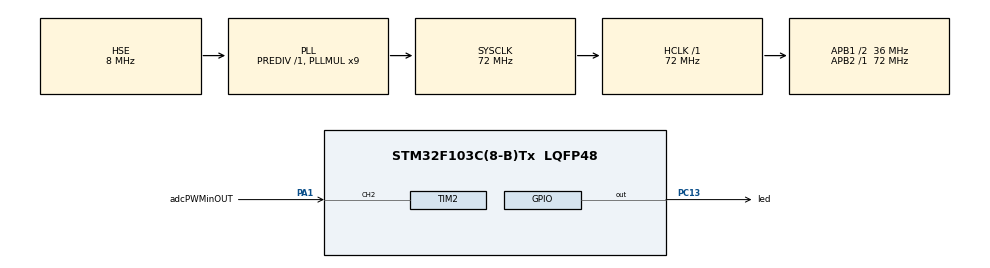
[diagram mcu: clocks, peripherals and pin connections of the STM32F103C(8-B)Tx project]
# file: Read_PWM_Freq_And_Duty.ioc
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Mcu.Family=STM32F1
Mcu.Name=STM32F103C(8-B)Tx
Mcu.Package=LQFP48
NVIC.PriorityGroup=NVIC_PRIORITYGROUP_4
NVIC.TIM2_IRQn=true\:1\:0\:true\:false\:true\:true\:true\:true
PA1.GPIO_Label=adcPWMinOUT
PA1.Signal=S_TIM2_CH2
PA13.Mode=Serial_Wire
PA13.Signal=SYS_JTMS-SWDIO
PA14.Mode=Serial_Wire
PA14.Signal=SYS_JTCK-SWCLK
PC13-TAMPER-RTC.GPIO_Label=led
PC13-TAMPER-RTC.Signal=GPIO_Output
PD0-OSC_IN.Mode=HSE-External-Oscillator
PD0-OSC_IN.Signal=RCC_OSC_IN
PD1-OSC_OUT.Mode=HSE-External-Oscillator
PD1-OSC_OUT.Signal=RCC_OSC_OUT
ProjectManager.HeapSize=0x200
ProjectManager.StackSize=0x400
ProjectManager.TargetToolchain=STM32CubeIDE
RCC.ADCPresc=RCC_ADCPCLK2_DIV8
RCC.AHBFreq_Value=72000000
RCC.APB1CLKDivider=RCC_HCLK_DIV2
RCC.APB1Freq_Value=36000000
RCC.APB1TimFreq_Value=72000000
RCC.APB2Freq_Value=72000000
RCC.APB2TimFreq_Value=72000000
RCC.HCLKFreq_Value=72000000
RCC.PLLMUL=RCC_PLL_MUL9
RCC.PLLSourceVirtual=RCC_PLLSOURCE_HSE
RCC.SYSCLKFreq_VALUE=72000000
RCC.SYSCLKSource=RCC_SYSCLKSOURCE_PLLCLK
RCC.USBFreq_Value=72000000
SH.S_TIM2_CH2.0=TIM2_CH2,PWM_Input_2
TIM2.Period=65535
TIM2.Prescaler=5-1
VP_TIM2_VS_ClockSourceINT.Mode=Internal
board=custom

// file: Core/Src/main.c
/* USER CODE BEGIN Header */
/**
  ******************************************************************************
  * @file           : main.c
  * @brief          : Main program body
  ******************************************************************************
  * @attention
  *
  * <h2><center>&copy; Copyright (c) 2025 STMicroelectronics.
  * All rights reserved.</center></h2>
  *
  * This software component is licensed by ST under Ultimate Liberty license
  * SLA0044, the "License"; You may not use this file except in compliance with
  * the License. You may obtain a copy of the License at:
  *                             www.st.com/SLA0044
  *
  ******************************************************************************
  */
/* USER CODE END Header */
#include "main.h"

/* USER CODE BEGIN Includes */
#include <math.h>
/* USER CODE END Includes */

/* USER CODE BEGIN PTD */
typedef struct {
	TIM_HandleTypeDef *htim;
	int32_t freq;
	int32_t dutyCycle;
	uint32_t capVal1;
	uint32_t capVal2;
} PWM_In;
/* USER CODE END PTD */

TIM_HandleTypeDef htim2;

/* USER CODE BEGIN PV */
PWM_In AS5600;
float AS5600_deg = 0;
/* USER CODE END PV */

void SystemClock_Config(void);
static void MX_GPIO_Init(void);
static void MX_TIM2_Init(void);

/* USER CODE BEGIN 0 */
float map_float_(float x, float in_min, float in_max, float out_min, float out_max) {
  return (x - in_min) * (out_max - out_min) / (in_max - in_min) + out_min;
}

void HAL_TIM_IC_CaptureCallback(TIM_HandleTypeDef *htim) {
	if (htim == &htim2) {
		if (htim2.Channel == HAL_TIM_ACTIVE_CHANNEL_2) {
			AS5600.capVal2 = htim2.Instance->CCR2; // get signal rising counter
			if (AS5600.capVal2) {
				AS5600.freq = (SystemCoreClock
						/ (htim2.Instance->PSC + 1)) / (AS5600.capVal2); //calculate freq with sysclock devide with htim psc
				AS5600.capVal1 = htim2.Instance->CCR1; //get signal falling counter
				AS5600.dutyCycle = 10000
						- (10000 * AS5600.capVal1 / AS5600.capVal2);
			}

		}
	}
}
/* USER CODE END 0 */

int main(void)
{

  /* MCU Configuration--------------------------------------------------------*/

  /* Reset of all peripherals, Initializes the Flash interface and the Systick. */
  HAL_Init();

  /* Configure the system clock */
  SystemClock_Config();

  /* Initialize all configured peripherals */
  MX_GPIO_Init();
  MX_TIM2_Init();
  /* USER CODE BEGIN 2 */
  HAL_TIM_IC_Start_IT(&htim2, TIM_CHANNEL_2);
  HAL_TIM_IC_Start_IT(&htim2, TIM_CHANNEL_1);
  /* USER CODE END 2 */

  /* Infinite loop */
  /* USER CODE BEGIN WHILE */
  while (1)
  {
	  AS5600_deg = map_float_((float)AS5600.dutyCycle, 0.0f, 10000.0f, 0.0f, 360.0f);
	  HAL_GPIO_TogglePin(led_GPIO_Port, led_Pin);
	  HAL_Delay(100);
    /* USER CODE END WHILE */

  }
}

void SystemClock_Config(void)
{
  RCC_OscInitTypeDef RCC_OscInitStruct = {0};
  RCC_ClkInitTypeDef RCC_ClkInitStruct = {0};

  /** Initializes the RCC Oscillators according to the specified parameters
  * in the RCC_OscInitTypeDef structure.
  */
  RCC_OscInitStruct.OscillatorType = RCC_OSCILLATORTYPE_HSE;
  RCC_OscInitStruct.HSEState = RCC_HSE_ON;
  RCC_OscInitStruct.HSEPredivValue = RCC_HSE_PREDIV_DIV1;
  RCC_OscInitStruct.HSIState = RCC_HSI_ON;
  RCC_OscInitStruct.PLL.PLLState = RCC_PLL_ON;
  RCC_OscInitStruct.PLL.PLLSource = RCC_PLLSOURCE_HSE;
  RCC_OscInitStruct.PLL.PLLMUL = RCC_PLL_MUL9;
  if (HAL_RCC_OscConfig(&RCC_OscInitStruct) != HAL_OK)
  {
    Error_Handler();
  }
  /** Initializes the CPU, AHB and APB buses clocks
  */
  RCC_ClkInitStruct.ClockType = RCC_CLOCKTYPE_HCLK|RCC_CLOCKTYPE_SYSCLK
                              |RCC_CLOCKTYPE_PCLK1|RCC_CLOCKTYPE_PCLK2;
  RCC_ClkInitStruct.SYSCLKSource = RCC_SYSCLKSOURCE_PLLCLK;
  RCC_ClkInitStruct.AHBCLKDivider = RCC_SYSCLK_DIV1;
  RCC_ClkInitStruct.APB1CLKDivider = RCC_HCLK_DIV2;
  RCC_ClkInitStruct.APB2CLKDivider = RCC_HCLK_DIV1;

  if (HAL_RCC_ClockConfig(&RCC_ClkInitStruct, FLASH_LATENCY_2) != HAL_OK)
  {
    Error_Handler();
  }
}

static void MX_TIM2_Init(void)
{

  TIM_ClockConfigTypeDef sClockSourceConfig = {0};
  TIM_SlaveConfigTypeDef sSlaveConfig = {0};
  TIM_IC_InitTypeDef sConfigIC = {0};
  TIM_MasterConfigTypeDef sMasterConfig = {0};

  htim2.Instance = TIM2;
  htim2.Init.Prescaler = 5-1;
  htim2.Init.CounterMode = TIM_COUNTERMODE_UP;
  htim2.Init.Period = 65535;
  htim2.Init.ClockDivision = TIM_CLOCKDIVISION_DIV1;
  htim2.Init.AutoReloadPreload = TIM_AUTORELOAD_PRELOAD_DISABLE;
  if (HAL_TIM_Base_Init(&htim2) != HAL_OK)
  {
    Error_Handler();
  }
  sClockSourceConfig.ClockSource = TIM_CLOCKSOURCE_INTERNAL;
  if (HAL_TIM_ConfigClockSource(&htim2, &sClockSourceConfig) != HAL_OK)
  {
    Error_Handler();
  }
  if (HAL_TIM_IC_Init(&htim2) != HAL_OK)
  {
    Error_Handler();
  }
  sSlaveConfig.SlaveMode = TIM_SLAVEMODE_RESET;
  sSlaveConfig.InputTrigger = TIM_TS_TI2FP2;
  sSlaveConfig.TriggerPolarity = TIM_INPUTCHANNELPOLARITY_FALLING;
  sSlaveConfig.TriggerPrescaler = TIM_ICPSC_DIV1;
  sSlaveConfig.TriggerFilter = 0;
  if (HAL_TIM_SlaveConfigSynchro(&htim2, &sSlaveConfig) != HAL_OK)
  {
    Error_Handler();
  }
  sConfigIC.ICPolarity = TIM_INPUTCHANNELPOLARITY_RISING;
  sConfigIC.ICSelection = TIM_ICSELECTION_INDIRECTTI;
  sConfigIC.ICPrescaler = TIM_ICPSC_DIV1;
  sConfigIC.ICFilter = 0;
  if (HAL_TIM_IC_ConfigChannel(&htim2, &sConfigIC, TIM_CHANNEL_1) != HAL_OK)
  {
    Error_Handler();
  }
  sConfigIC.ICPolarity = TIM_INPUTCHANNELPOLARITY_FALLING;
  sConfigIC.ICSelection = TIM_ICSELECTION_DIRECTTI;
  if (HAL_TIM_IC_ConfigChannel(&htim2, &sConfigIC, TIM_CHANNEL_2) != HAL_OK)
  {
    Error_Handler();
  }
  sMasterConfig.MasterOutputTrigger = TIM_TRGO_RESET;
  sMasterConfig.MasterSlaveMode = TIM_MASTERSLAVEMODE_DISABLE;
  if (HAL_TIMEx_MasterConfigSynchronization(&htim2, &sMasterConfig) != HAL_OK)
  {
    Error_Handler();
  }

}

static void MX_GPIO_Init(void)
{
  GPIO_InitTypeDef GPIO_InitStruct = {0};

  /* GPIO Ports Clock Enable */
  __HAL_RCC_GPIOC_CLK_ENABLE();
  __HAL_RCC_GPIOD_CLK_ENABLE();
  __HAL_RCC_GPIOA_CLK_ENABLE();

  /*Configure GPIO pin Output Level */
  HAL_GPIO_WritePin(led_GPIO_Port, led_Pin, GPIO_PIN_RESET);

  /*Configure GPIO pin : led_Pin */
  GPIO_InitStruct.Pin = led_Pin;
  GPIO_InitStruct.Mode = GPIO_MODE_OUTPUT_PP;
  GPIO_InitStruct.Pull = GPIO_NOPULL;
  GPIO_InitStruct.Speed = GPIO_SPEED_FREQ_LOW;
  HAL_GPIO_Init(led_GPIO_Port, &GPIO_InitStruct);

}

void Error_Handler(void)
{
  __disable_irq();
  while (1)
  {
  }
}

/************************ (C) COPYRIGHT STMicroelectronics *****END OF FILE****/
